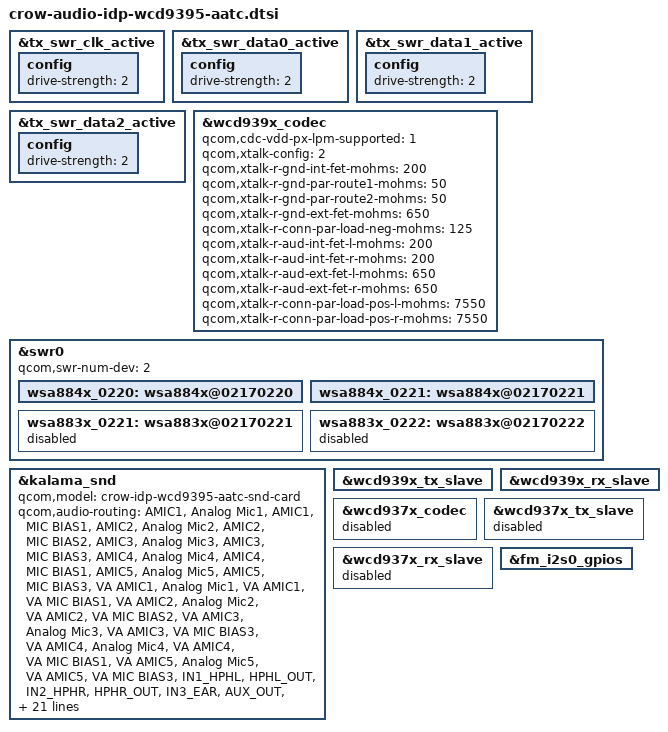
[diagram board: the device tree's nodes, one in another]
#include "crow-audio-overlay.dtsi"

&tx_swr_clk_active {
	config {
		drive-strength = <2>;
	};
};

&tx_swr_data0_active {
	config {
		drive-strength = <2>;
	};
};

&tx_swr_data1_active {
	config {
		drive-strength = <2>;
	};
};

&tx_swr_data2_active {
	config {
		drive-strength = <2>;
	};
};

&wcd939x_codec {
	qcom,cdc-vdd-px-lpm-supported = <1>;
	/* 0 for no crosstalk, 1 for digital crosstalk, and 2 for analog crosstalk */
	qcom,xtalk-config = <2>;
	qcom,xtalk-r-gnd-int-fet-mohms = <200>;
	qcom,xtalk-r-gnd-par-route1-mohms = <50>;
	qcom,xtalk-r-gnd-par-route2-mohms = <50>;
	qcom,xtalk-r-gnd-ext-fet-mohms = <650>;
	qcom,xtalk-r-conn-par-load-neg-mohms = <125>;
	qcom,xtalk-r-aud-int-fet-l-mohms = <200>;
	qcom,xtalk-r-aud-int-fet-r-mohms = <200>;
	qcom,xtalk-r-aud-ext-fet-l-mohms = <650>;
	qcom,xtalk-r-aud-ext-fet-r-mohms = <650>;
	qcom,xtalk-r-conn-par-load-pos-l-mohms = <7550>;
	qcom,xtalk-r-conn-par-load-pos-r-mohms = <7550>;
};

&swr0 {
	qcom,swr-num-dev = <2>;

	wsa884x_0220: wsa884x@02170220 {
		status = "okay";
	};

	wsa884x_0221: wsa884x@02170221 {
		status = "okay";
	};

	wsa883x_0221: wsa883x@02170221 {
		status = "disabled";
	};

	wsa883x_0222: wsa883x@02170222 {
		status = "disabled";
	};
};

&kalama_snd {
	qcom,model = "crow-idp-wcd9395-aatc-snd-card";

	qcom,audio-routing =
		"AMIC1", "Analog Mic1",
		"AMIC1", "MIC BIAS1",
		"AMIC2", "Analog Mic2",
		"AMIC2", "MIC BIAS2",
		"AMIC3", "Analog Mic3",
		"AMIC3", "MIC BIAS3",
		"AMIC4", "Analog Mic4",
		"AMIC4", "MIC BIAS1",
		"AMIC5", "Analog Mic5",
		"AMIC5", "MIC BIAS3",
		"VA AMIC1", "Analog Mic1",
		"VA AMIC1", "VA MIC BIAS1",
		"VA AMIC2", "Analog Mic2",
		"VA AMIC2", "VA MIC BIAS2",
		"VA AMIC3", "Analog Mic3",
		"VA AMIC3", "VA MIC BIAS3",
		"VA AMIC4", "Analog Mic4",
		"VA AMIC4", "VA MIC BIAS1",
		"VA AMIC5", "Analog Mic5",
		"VA AMIC5", "VA MIC BIAS3",
		"IN1_HPHL", "HPHL_OUT",
		"IN2_HPHR", "HPHR_OUT",
		"IN3_EAR", "AUX_OUT",
		"WSA SRC0_INP", "SRC0",
		"WSA_TX DEC0_INP", "TX DEC0 MUX",
		"WSA_TX DEC1_INP", "TX DEC1 MUX",
		"RX_TX DEC0_INP", "TX DEC0 MUX",
		"RX_TX DEC1_INP", "TX DEC1 MUX",
		"RX_TX DEC2_INP", "TX DEC2 MUX",
		"RX_TX DEC3_INP", "TX DEC3 MUX",
		"SpkrLeft IN", "WSA_SPK1 OUT",
		"SpkrRight IN", "WSA_SPK2 OUT",
		"TX SWR_INPUT", "WCD_TX_OUTPUT",
		"VA SWR_INPUT", "VA_SWR_CLK",
		"VA SWR_INPUT", "WCD_TX_OUTPUT",
		"VA_AIF1 CAP", "VA_SWR_CLK",
		"VA_AIF2 CAP", "VA_SWR_CLK",
		"VA_AIF3 CAP", "VA_SWR_CLK";
	asoc-codec  = <&stub_codec>, <&lpass_cdc>,
			<&wcd939x_codec>, <&wsa884x_0220>, <&wsa884x_0221>;
	asoc-codec-names = "msm-stub-codec.1", "lpass-cdc",
			"wcd939x_codec", "wsa-codec1", "wsa-codec2";
	qcom,msm-mbhc-usbc-audio-supported = <1>;
	qcom,msm-mbhc-hphl-swh = <0>;
	qcom,msm-mbhc-gnd-swh = <0>;
	qcom,wcd-disable-legacy-surge;
	wcd939x-i2c-handle = <&wcd_usbss>;
	qcom,ext-disp-audio-rx = <1>;
	qcom,pri-mi2s-gpios = <&fm_i2s0_gpios>;
};

&wcd939x_codec {
	status = "okay";
};

&wcd939x_tx_slave {
	status = "okay";
};

&wcd939x_rx_slave {
	status = "okay";
};

&wcd937x_codec {
	status = "disabled";
};

&wcd937x_tx_slave {
	status = "disabled";
};

&wcd937x_rx_slave {
	status = "disabled";
};

&fm_i2s0_gpios {
	status = "ok";
};
